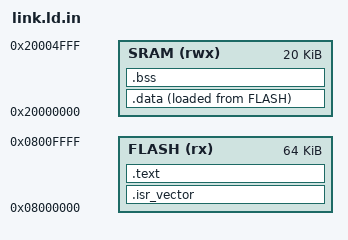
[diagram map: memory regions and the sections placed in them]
/* Linker script for the BLE-stress C firmware. Mirrors the FLASH/SRAM origins of
 * runtime-hal/harness/build_assets/gd32f10x/link.ld; the LENGTHs are the real part's, and the
 * SECTIONS carry the data-init/bss symbols the C startup needs (the harness ld has no real crt).
 *
 * This file is PREPROCESSED (`gcc -E -P -x c`) into build/link.ld so that the one script covers both
 * board variants: only the two MEMORY lengths differ, and forking fifty lines of identical SECTIONS to
 * change two numbers is how the two scripts silently drift apart. The Makefile passes the same -DBOARD
 * it passes to the C.
 *
 *   BOARD_BENCH   GD32F103C8 (medium density): 64 KiB flash @ 0x08000000, 20 KiB SRAM @ 0x20000000
 *   BOARD_OFFROAD GD32F130 (offroad master):   64 KiB flash @ 0x08000000,  8 KiB SRAM @ 0x20000000
 *
 * The F130's SRAM is 8 KiB, and that is the number that matters: _estack is placed at the TOP of SRAM,
 * so a 20 KiB length on an 8 KiB part puts the initial stack pointer past the end of physical RAM and
 * the core faults on the first push, before main. Nothing in this image is large enough to care about
 * the difference otherwise.
 *
 * Both parts are 64 KiB flash and the whole image is ~2.5 KiB, so the F1x0 zero-wait-first-32-KiB
 * window (see crates/firmware/memory.x) is not a constraint here: everything is well inside it. */

#define BOARD_BENCH   0
#define BOARD_OFFROAD 1

#ifndef BOARD
#define BOARD BOARD_BENCH
#endif

#if BOARD == BOARD_OFFROAD
#define SRAM_LENGTH 8K
#else
#define SRAM_LENGTH 20K
#endif

ENTRY(Reset_Handler)

MEMORY
{
    FLASH (rx)  : ORIGIN = 0x08000000, LENGTH = 64K
    SRAM  (rwx) : ORIGIN = 0x20000000, LENGTH = SRAM_LENGTH
}

_estack = ORIGIN(SRAM) + LENGTH(SRAM);

SECTIONS
{
    .isr_vector : {
        KEEP(*(.isr_vector))
    } > FLASH

    .text : {
        *(.text*)
        *(.rodata*)
        . = ALIGN(4);
    } > FLASH

    _sidata = LOADADDR(.data);

    .data : {
        . = ALIGN(4);
        _sdata = .;
        *(.data*)
        . = ALIGN(4);
        _edata = .;
    } > SRAM AT > FLASH

    .bss : {
        . = ALIGN(4);
        _sbss = .;
        *(.bss*)
        *(COMMON)
        . = ALIGN(4);
        _ebss = .;
    } > SRAM

    . = ALIGN(4);
    _end = .;

    /DISCARD/ : {
        *(.ARM.exidx*)
        *(.ARM.attributes)
    }
}
